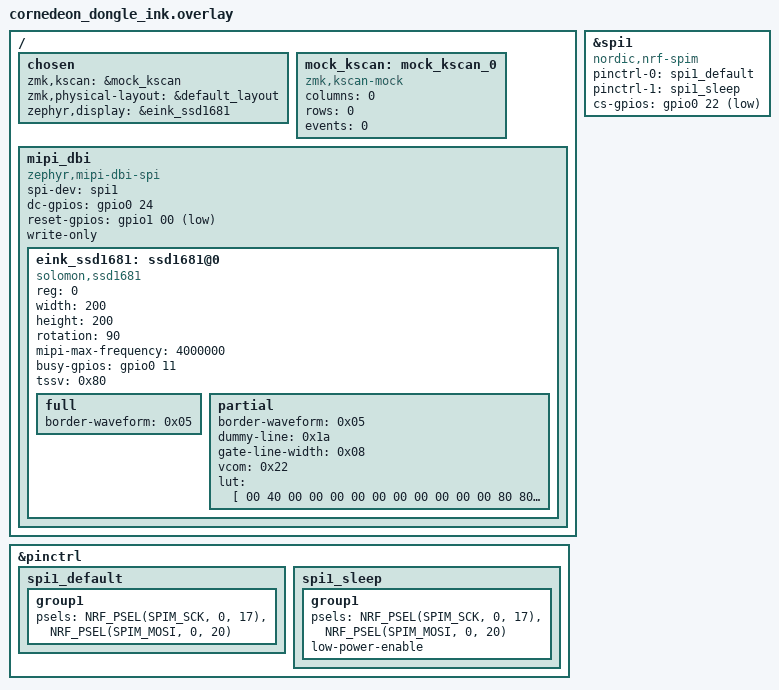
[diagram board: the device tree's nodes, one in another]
#include "cornedeon.dtsi"

/ {
    chosen {
        zmk,kscan = &mock_kscan;
        zmk,physical-layout = &default_layout;
    };

    mock_kscan: mock_kscan_0 {
        compatible = "zmk,kscan-mock";
        columns = <0>;
        rows = <0>;
        events = <0>;
    };

};

&pinctrl {
   spi1_default: spi1_default {
		group1 {
			psels = <NRF_PSEL(SPIM_SCK, 0, 17)>,
				<NRF_PSEL(SPIM_MOSI, 0, 20)>;
		};
	};

	spi1_sleep: spi1_sleep {
		group1 {
			psels = <NRF_PSEL(SPIM_SCK, 0, 17)>,
				<NRF_PSEL(SPIM_MOSI, 0, 20)>;
			low-power-enable;
		};
	};
};

&spi1 {
	status = "okay";
	compatible = "nordic,nrf-spim";
	pinctrl-0 = <&spi1_default>;
	pinctrl-1 = <&spi1_sleep>;
	pinctrl-names = "default", "sleep";
	cs-gpios = <&gpio0 22 GPIO_ACTIVE_LOW>;
};

/ {
    mipi_dbi {
       compatible = "zephyr,mipi-dbi-spi";
       spi-dev = <&spi1>;
       dc-gpios = <&gpio0 24 GPIO_ACTIVE_HIGH>;
       reset-gpios = <&gpio1 00 GPIO_ACTIVE_LOW>;
       write-only;
       #address-cells = <1>;
       #size-cells = <0>;

      eink_ssd1681: ssd1681@0 {
			compatible = "solomon,ssd1681";
			status = "okay";
			reg = <0>;
			width = <200>;
			height = <200>;
			rotation = <90>;

			mipi-max-frequency = <4000000>;
			busy-gpios = <&gpio0 11 GPIO_ACTIVE_HIGH>;
			tssv = <0x80>;

			full {
				border-waveform = <0x05>;
			};

			partial {
				border-waveform = <0x05>;
				dummy-line = <0x1a>;
				gate-line-width = <0x08>;
				vcom = <0x22>;
				lut = [
				/* Voltage actions, 12 bytes per row */
				00 40 00 00 00 00 00 00 00 00 00 00
				80 80 00 00 00 00 00 00 00 00 00 00
				40 40 00 00 00 00 00 00 00 00 00 00
				00 80 00 00 00 00 00 00 00 00 00 00
				00 00 00 00 00 00 00 00 00 00 00 00

				/* Timing controls, 7 bytes per row */
				0F 00 00 00 00 00 00
				01 01 00 00 00 00 00
				00 00 00 00 00 00 00
				00 00 00 00 00 00 00
				00 00 00 00 00 00 00
				00 00 00 00 00 00 00
				00 00 00 00 00 00 00
				00 00 00 00 00 00 00
				00 00 00 00 00 00 00
				00 00 00 00 00 00 00
				00 00 00 00 00 00 00
				00 00 00 00 00 00 00

				/* Voltage levels, 9 bytes */
				22 22 22 22 22 22 00 00 00
				];
			};
		};
    };

    chosen {
		zephyr,display = &eink_ssd1681;
	};
};

